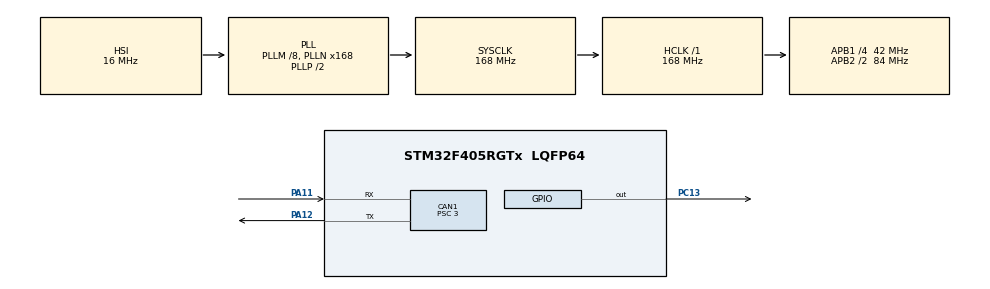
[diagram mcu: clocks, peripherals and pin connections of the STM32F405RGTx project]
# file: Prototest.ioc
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CAN1.BS1=CAN_BS1_10TQ
CAN1.BS2=CAN_BS2_3TQ
CAN1.CalculateBaudRate=1000000
CAN1.CalculateTimeBit=1000
CAN1.CalculateTimeQuantum=71.42857142857143
CAN1.Prescaler=3
FREERTOS.Tasks01=defaultTask,24,128,StartDefaultTask,Default,NULL,Dynamic,NULL,NULL;myTask02,40,512,StartTask02,Default,NULL,Dynamic,NULL,NULL
Mcu.Family=STM32F4
Mcu.Name=STM32F405RGTx
Mcu.Package=LQFP64
NVIC.CAN1_RX0_IRQn=true\:5\:0\:false\:false\:true\:true\:true\:true\:true
NVIC.CAN1_RX1_IRQn=true\:5\:0\:false\:false\:true\:true\:true\:true\:true
NVIC.PriorityGroup=NVIC_PRIORITYGROUP_4
NVIC.TIM6_DAC_IRQn=true\:15\:0\:false\:false\:true\:false\:false\:true\:true
NVIC.TimeBase=TIM6_DAC_IRQn
NVIC.TimeBaseIP=TIM6
PA11.Mode=CAN_Activate
PA11.Signal=CAN1_RX
PA12.Mode=CAN_Activate
PA12.Signal=CAN1_TX
PA13.Mode=Serial_Wire
PA13.Signal=SYS_JTMS-SWDIO
PA14.Mode=Serial_Wire
PA14.Signal=SYS_JTCK-SWCLK
PC13-ANTI_TAMP.PinState=GPIO_PIN_SET
PC13-ANTI_TAMP.Signal=GPIO_Output
PC14-OSC32_IN.Mode=LSE-External-Oscillator
PC14-OSC32_IN.Signal=RCC_OSC32_IN
PC15-OSC32_OUT.Mode=LSE-External-Oscillator
PC15-OSC32_OUT.Signal=RCC_OSC32_OUT
PH0-OSC_IN.Mode=HSE-External-Oscillator
PH0-OSC_IN.Signal=RCC_OSC_IN
PH1-OSC_OUT.Mode=HSE-External-Oscillator
PH1-OSC_OUT.Signal=RCC_OSC_OUT
ProjectManager.HeapSize=0x200
ProjectManager.StackSize=0x400
ProjectManager.TargetToolchain=MDK-ARM V5.32
RCC.48MHZClocksFreq_Value=84000000
RCC.AHBFreq_Value=168000000
RCC.APB1CLKDivider=RCC_HCLK_DIV4
RCC.APB1Freq_Value=42000000
RCC.APB1TimFreq_Value=84000000
RCC.APB2CLKDivider=RCC_HCLK_DIV2
RCC.APB2Freq_Value=84000000
RCC.APB2TimFreq_Value=168000000
RCC.CortexFreq_Value=168000000
RCC.HCLKFreq_Value=168000000
RCC.HSE_VALUE=25000000
RCC.HSI_VALUE=16000000
RCC.PLLM=8
RCC.PLLN=168
RCC.SYSCLKFreq_VALUE=168000000
RCC.SYSCLKSource=RCC_SYSCLKSOURCE_PLLCLK
RCC.VCOOutputFreq_Value=336000000
VP_FREERTOS_VS_CMSIS_V2.Mode=CMSIS_V2
VP_SYS_VS_tim6.Mode=TIM6
board=custom

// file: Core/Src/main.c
/* USER CODE BEGIN Header */
/**
  ******************************************************************************
  * @file           : main.c
  * @brief          : Main program body
  ******************************************************************************
  * @attention
  *
  * Copyright (c) 2025 STMicroelectronics.
  * All rights reserved.
  *
  * This software is licensed under terms that can be found in the LICENSE file
  * in the root directory of this software component.
  * If no LICENSE file comes with this software, it is provided AS-IS.
  *
  ******************************************************************************
  */
/* USER CODE END Header */
#include "main.h"
#include "cmsis_os.h"
#include "can.h"
#include "gpio.h"

/* USER CODE BEGIN PTD */
//滤波器编�????
#define CAN_FILTER(x) ((x) << 3)

//接收队列
#define CAN_FIFO_0 (0 << 2)
#define CAN_FIFO_1 (1 << 2)

//标准帧或扩展�????
#define CAN_STDID (0 << 1)
#define CAN_EXTID (1 << 1)

//数据帧或遥控�????
#define CAN_DATA_TYPE (0 << 0)
#define CAN_REMOTE_TYPE (1 << 0)

/* USER CODE END PTD */

/* USER CODE BEGIN PV */
Motor GM6020;

CAN_RxHeaderTypeDef header;
uint8_t CAN_Rx_Data[8];
uint16_t IT = 0;
uint8_t success = 0;
uint16_t testflag = 0;

/* USER CODE END PV */

void SystemClock_Config(void);
void MX_FREERTOS_Init(void);

/* USER CODE BEGIN 0 */
void CAN_Init(CAN_HandleTypeDef *hcan)
{
  HAL_CAN_Start(hcan);
  __HAL_CAN_ENABLE_IT(hcan, CAN_IT_RX_FIFO0_MSG_PENDING);
  __HAL_CAN_ENABLE_IT(hcan, CAN_IT_RX_FIFO1_MSG_PENDING);
}
uint8_t CAN_Send_Data(CAN_HandleTypeDef *hcan, uint16_t ID, uint8_t *Data, uint16_t Length)
{
  CAN_TxHeaderTypeDef tx_hander;
  uint32_t used_mailbox;

  assert_param(hcan != NULL);

  tx_hander.StdId = ID;
  tx_hander.ExtId = 0;
  tx_hander.IDE = CAN_ID_STD;
  tx_hander.RTR = CAN_RTR_DATA;
  tx_hander.DLC = Length;

  return HAL_CAN_AddTxMessage(hcan, &tx_hander, Data, &used_mailbox);
}

void CAN_Filter_Mask_Config(CAN_HandleTypeDef *hcan, uint8_t Object_Para, uint32_t ID, uint32_t Mask_ID)
{
  CAN_FilterTypeDef can_filter_init;

  assert_param(hcan != NULL);

  if(Object_Para & 0x02)
  {
    //数据�????
    can_filter_init.FilterIdHigh = ID << 3 << 16;
    can_filter_init.FilterIdLow = ID << 3 | ((Object_Para & 0x03) << 1);
    can_filter_init.FilterMaskIdHigh = Mask_ID << 3 <<16;
    can_filter_init.FilterMaskIdLow = Mask_ID << 3 | ((Object_Para & 0x03) << 1);
  }
  else
  {
    //遥控�????
    can_filter_init.FilterIdHigh = ID << 5;
    can_filter_init.FilterIdLow = ((Object_Para & 0x03) << 1);
    can_filter_init.FilterMaskIdHigh = Mask_ID << 5;
    can_filter_init.FilterMaskIdLow = ((Object_Para & 0x03) << 1);
  }
  can_filter_init.FilterBank = Object_Para >> 3;
  can_filter_init.FilterFIFOAssignment = (Object_Para >> 2) & 0x01;
  can_filter_init.FilterActivation = ENABLE;
  can_filter_init.FilterMode = CAN_FILTERMODE_IDMASK;
  can_filter_init.FilterScale = CAN_FILTERSCALE_32BIT;
  can_filter_init.SlaveStartFilterBank = 14;

  HAL_CAN_ConfigFilter(hcan, &can_filter_init);
}

void Send_Motor_V(uint16_t ID, float voltage)
{
  if(voltage > 24.0f)  voltage = 24.0f;
  else if(voltage < -24.0f)  voltage = -24.0f;

  uint16_t raw_voltage = (uint16_t)(voltage * 1000.0f);
  uint8_t CAN_Tx_Data[8];
  CAN_Tx_Data[0] = (raw_voltage >> 8) & 0xff;
  CAN_Tx_Data[1] = raw_voltage & 0xff;

  CAN_Send_Data(&hcan1, ID, CAN_Tx_Data, 8);
}

void Motor_Feedback(uint8_t *data)
{
  GM6020.raw_angle = (data[0] << 8) | data[1];
  GM6020.raw_rpm = (data[2] << 8) | data[3];
  GM6020.raw_current = (data[4] << 8) | data[5];
  GM6020.raw_temperature = data[6];

  GM6020.current_angle = (GM6020.raw_angle / 8191.0f) * 360.0f;
  GM6020.current = (GM6020.raw_current / 16384.0f) * 3.0f;
  GM6020.rpm = GM6020.raw_rpm * 1.0f;

  GM6020.raw_current_angle = (data[0] << 8) | data[1];
  int16_t delta = GM6020.raw_current_angle - GM6020.raw_last_angle;

  if(delta > 4096)
  {
    delta -= 8191;
    GM6020.circle_count--;
  }
  else if(delta < -4096)
  {
    delta += 8191;
    GM6020.circle_count++;
  }

  GM6020.total_angle += (delta / 8191.0f) * 360.0f;
  GM6020.raw_last_angle = GM6020.raw_current_angle;

}
/* USER CODE END 0 */

int main(void)
{

  /* MCU Configuration--------------------------------------------------------*/

  /* Reset of all peripherals, Initializes the Flash interface and the Systick. */
  HAL_Init();

  /* Configure the system clock */
  SystemClock_Config();

  /* Initialize all configured peripherals */
  MX_GPIO_Init();
  MX_CAN1_Init();
  /* USER CODE BEGIN 2 */
  CAN_Init(&hcan1);
  CAN_Filter_Mask_Config(&hcan1, CAN_FILTER(13) | CAN_FIFO_1 | CAN_STDID | CAN_DATA_TYPE, 0x205, 0x7ff);
  HAL_CAN_ActivateNotification(&hcan1, CAN_IT_RX_FIFO1_MSG_PENDING);
  /* USER CODE END 2 */

  /* Init scheduler */
  osKernelInitialize();

  /* Call init function for freertos objects (in cmsis_os2.c) */
  MX_FREERTOS_Init();

  /* Start scheduler */
  osKernelStart();

  /* We should never get here as control is now taken by the scheduler */

  /* Infinite loop */
  while (1)
  {

  }
}

void SystemClock_Config(void)
{
  RCC_OscInitTypeDef RCC_OscInitStruct = {0};
  RCC_ClkInitTypeDef RCC_ClkInitStruct = {0};

  /** Configure the main internal regulator output voltage
  */
  __HAL_RCC_PWR_CLK_ENABLE();
  __HAL_PWR_VOLTAGESCALING_CONFIG(PWR_REGULATOR_VOLTAGE_SCALE1);

  /** Initializes the RCC Oscillators according to the specified parameters
  * in the RCC_OscInitTypeDef structure.
  */
  RCC_OscInitStruct.OscillatorType = RCC_OSCILLATORTYPE_HSI;
  RCC_OscInitStruct.HSIState = RCC_HSI_ON;
  RCC_OscInitStruct.HSICalibrationValue = RCC_HSICALIBRATION_DEFAULT;
  RCC_OscInitStruct.PLL.PLLState = RCC_PLL_ON;
  RCC_OscInitStruct.PLL.PLLSource = RCC_PLLSOURCE_HSI;
  RCC_OscInitStruct.PLL.PLLM = 8;
  RCC_OscInitStruct.PLL.PLLN = 168;
  RCC_OscInitStruct.PLL.PLLP = RCC_PLLP_DIV2;
  RCC_OscInitStruct.PLL.PLLQ = 4;
  if (HAL_RCC_OscConfig(&RCC_OscInitStruct) != HAL_OK)
  {
    Error_Handler();
  }

  /** Initializes the CPU, AHB and APB buses clocks
  */
  RCC_ClkInitStruct.ClockType = RCC_CLOCKTYPE_HCLK|RCC_CLOCKTYPE_SYSCLK
                              |RCC_CLOCKTYPE_PCLK1|RCC_CLOCKTYPE_PCLK2;
  RCC_ClkInitStruct.SYSCLKSource = RCC_SYSCLKSOURCE_PLLCLK;
  RCC_ClkInitStruct.AHBCLKDivider = RCC_SYSCLK_DIV1;
  RCC_ClkInitStruct.APB1CLKDivider = RCC_HCLK_DIV4;
  RCC_ClkInitStruct.APB2CLKDivider = RCC_HCLK_DIV2;

  if (HAL_RCC_ClockConfig(&RCC_ClkInitStruct, FLASH_LATENCY_5) != HAL_OK)
  {
    Error_Handler();
  }
}

/* USER CODE BEGIN 4 */
void HAL_CAN_RxFifo1MsgPendingCallback(CAN_HandleTypeDef *hcan)
{
  if(hcan->Instance == CAN1)
  {
    HAL_CAN_GetRxMessage(hcan, CAN_FILTER_FIFO1, &header, CAN_Rx_Data);
    IT++;
    if(header.StdId == 0x205)
    {
      // IT++;
      Motor_Feedback(CAN_Rx_Data);
    }
  }
}
/* USER CODE END 4 */

void HAL_TIM_PeriodElapsedCallback(TIM_HandleTypeDef *htim)
{
  if (htim->Instance == TIM6) {
    HAL_IncTick();
  }
}

void Error_Handler(void)
{
  __disable_irq();
  while (1)
  {
  }
}

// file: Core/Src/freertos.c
/* USER CODE BEGIN Header */
/**
  ******************************************************************************
  * File Name          : freertos.c
  * Description        : Code for freertos applications
  ******************************************************************************
  * @attention
  *
  * Copyright (c) 2025 STMicroelectronics.
  * All rights reserved.
  *
  * This software is licensed under terms that can be found in the LICENSE file
  * in the root directory of this software component.
  * If no LICENSE file comes with this software, it is provided AS-IS.
  *
  ******************************************************************************
  */
/* USER CODE END Header */

#include "FreeRTOS.h"
#include "task.h"
#include "main.h"
#include "cmsis_os.h"

/* Definitions for defaultTask */
osThreadId_t defaultTaskHandle;
const osThreadAttr_t defaultTask_attributes = {
  .name = "defaultTask",
  .stack_size = 128 * 4,
  .priority = (osPriority_t) osPriorityNormal,
};
/* Definitions for myTask02 */
osThreadId_t myTask02Handle;
const osThreadAttr_t myTask02_attributes = {
  .name = "myTask02",
  .stack_size = 512 * 4,
  .priority = (osPriority_t) osPriorityHigh,
};

void StartDefaultTask(void *argument);
void StartTask02(void *argument);

void MX_FREERTOS_Init(void); /* (MISRA C 2004 rule 8.1) */

void MX_FREERTOS_Init(void) {

  /* Create the thread(s) */
  /* creation of defaultTask */
  defaultTaskHandle = osThreadNew(StartDefaultTask, NULL, &defaultTask_attributes);

  /* creation of myTask02 */
  myTask02Handle = osThreadNew(StartTask02, NULL, &myTask02_attributes);

}

void StartDefaultTask(void *argument)
{
  for(;;)
  {
    osDelay(1);
  }
}

void StartTask02(void *argument)
{
  /* USER CODE BEGIN StartTask02 */
  uint16_t torque;
  torque = 4000;
  uint8_t CAN_Tx_Data[8];
//  CAN_Tx_Data[0] = 0x22;
//  CAN_Tx_Data[1] = 0x00;
	// CAN_Tx_Data[2] = (torque >> 8) & 0xff;
  // CAN_Tx_Data[3] = torque & 0xff;
  CAN_Tx_Data[0] = 0x03;
  CAN_Tx_Data[1] = 0x05;
  CAN_Tx_Data[2] = 0x04;
  CAN_Tx_Data[3] = 0x08;
  CAN_Tx_Data[4] = 0x01;
  CAN_Tx_Data[5] = 0x02;
  CAN_Tx_Data[6] = 0x07;
  CAN_Tx_Data[7] = 0x06;
  /* Infinite loop */
  for(;;)
  {
    CAN_Send_Data(&hcan1, 0x1ff, CAN_Tx_Data, 8);
    if(CAN_Rx_Data[0] == 0x00 && CAN_Rx_Data[7] == 0x07)
		{
			success = 1;
		}
		else
		{
			success = 0;
		}
		if(success == 1)
		{
			HAL_GPIO_WritePin(GPIOC, GPIO_PIN_13, GPIO_PIN_RESET);
		}
		else if(success == 0)
		{
			HAL_GPIO_WritePin(GPIOC, GPIO_PIN_13, GPIO_PIN_SET);
		}

    osDelay(1);
  }
  /* USER CODE END StartTask02 */
}
